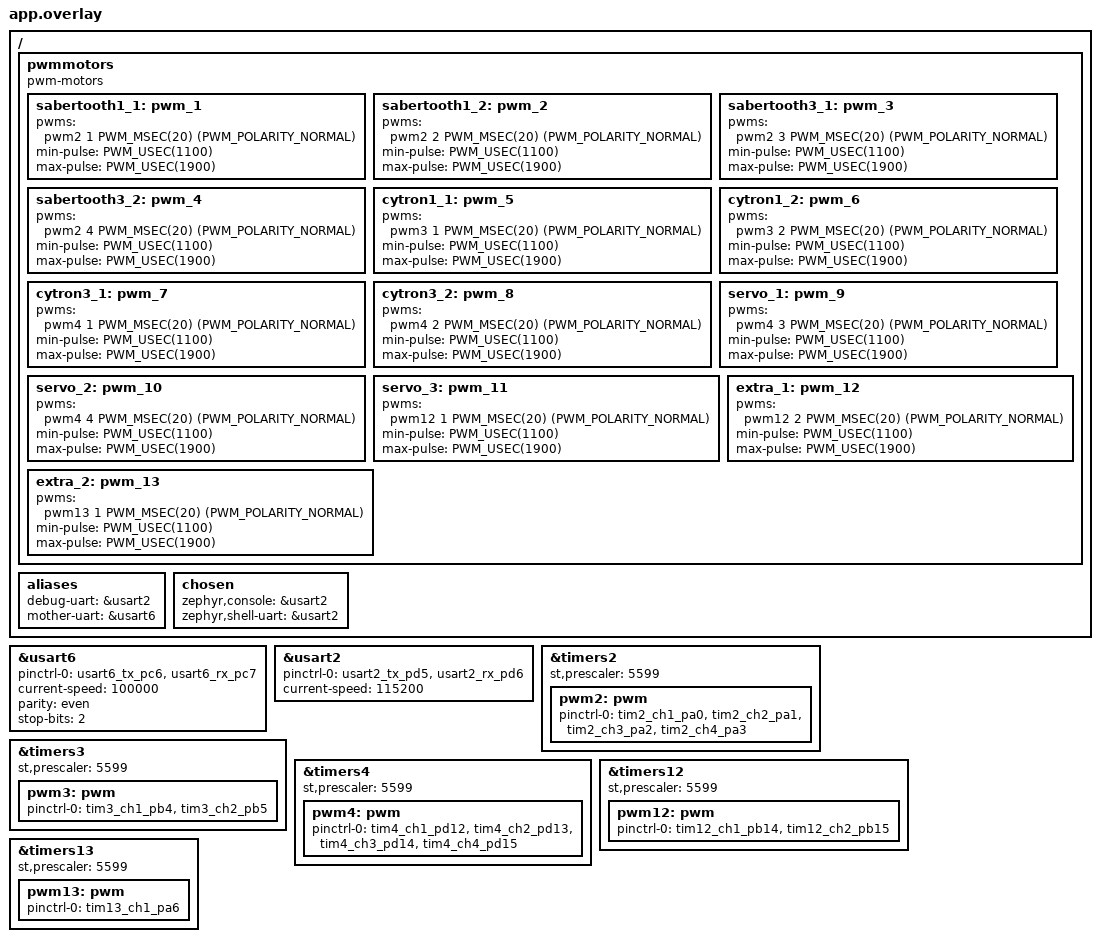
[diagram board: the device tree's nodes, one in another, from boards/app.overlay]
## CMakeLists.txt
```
cmake_minimum_required(VERSION 3.13.1)
set(DTC_OVERLAY_FILE "boards/app.overlay")
find_package(Zephyr REQUIRED HINTS $ENV{ZEPHYR_BASE})
project(R2-D2 LANGUAGES C)

target_sources(app PRIVATE src/UART_RAW_DATA_TEST.c)
```

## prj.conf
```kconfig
CONFIG_PRINTK=y
CONFIG_SERIAL=y
CONFIG_UART_INTERRUPT_DRIVEN=y

CONFIG_KYVERNITIS=y
CONFIG_CANSCRIBE=y
CONFIG_CANARD=y

CONFIG_CBPRINTF_FP_SUPPORT=y
CONFIG_REBOOT=y
```

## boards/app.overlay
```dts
#include <zephyr/dt-bindings/sensor/qdec_stm32.h>
/{
	pwmmotors {
		compatible = "pwm-motors";
		sabertooth1_1: pwm_1 {
			pwms  = <&pwm2 1 PWM_MSEC(20) (PWM_POLARITY_NORMAL)>;
			min-pulse = <PWM_USEC(1100)>;
			max-pulse = <PWM_USEC(1900)>;
		};
		sabertooth1_2: pwm_2 {
			pwms  = <&pwm2 2 PWM_MSEC(20) (PWM_POLARITY_NORMAL)>;
			min-pulse = <PWM_USEC(1100)>;
			max-pulse = <PWM_USEC(1900)>;
		};
		sabertooth3_1: pwm_3 {
			pwms  = <&pwm2 3 PWM_MSEC(20) (PWM_POLARITY_NORMAL)>;
			min-pulse = <PWM_USEC(1100)>;
			max-pulse = <PWM_USEC(1900)>;
		};
		sabertooth3_2: pwm_4 {
			pwms  = <&pwm2 4 PWM_MSEC(20) (PWM_POLARITY_NORMAL)>;
			min-pulse = <PWM_USEC(1100)>;
			max-pulse = <PWM_USEC(1900)>;
		};
		cytron1_1: pwm_5 {
			pwms  = <&pwm3 1 PWM_MSEC(20) (PWM_POLARITY_NORMAL)>;
			min-pulse = <PWM_USEC(1100)>;
			max-pulse = <PWM_USEC(1900)>;
		};
		cytron1_2: pwm_6 {
			pwms  = <&pwm3 2 PWM_MSEC(20) (PWM_POLARITY_NORMAL)>;
			min-pulse = <PWM_USEC(1100)>;
			max-pulse = <PWM_USEC(1900)>;
		};
		cytron3_1: pwm_7 {
			pwms  = <&pwm4 1 PWM_MSEC(20) (PWM_POLARITY_NORMAL)>;
			min-pulse = <PWM_USEC(1100)>;
			max-pulse = <PWM_USEC(1900)>;
		};
		cytron3_2: pwm_8 {
			pwms  = <&pwm4 2 PWM_MSEC(20) (PWM_POLARITY_NORMAL)>;
			min-pulse = <PWM_USEC(1100)>;
			max-pulse = <PWM_USEC(1900)>;
		};
		servo_1: pwm_9 {
			pwms  = <&pwm4 3 PWM_MSEC(20) (PWM_POLARITY_NORMAL)>;
			min-pulse = <PWM_USEC(1100)>;
			max-pulse = <PWM_USEC(1900)>;
		};
		servo_2: pwm_10 {
			pwms  = <&pwm4 4 PWM_MSEC(20) (PWM_POLARITY_NORMAL)>;
			min-pulse = <PWM_USEC(1100)>;
			max-pulse = <PWM_USEC(1900)>;
		};
		servo_3: pwm_11 {
			pwms  = <&pwm12 1 PWM_MSEC(20) (PWM_POLARITY_NORMAL)>;
			min-pulse = <PWM_USEC(1100)>;
			max-pulse = <PWM_USEC(1900)>;
		};

		extra_1: pwm_12 {
			pwms = <&pwm12 2 PWM_MSEC(20)  (PWM_POLARITY_NORMAL)>;
			min-pulse = <PWM_USEC(1100)>;
			max-pulse = <PWM_USEC(1900)>;
		};

		extra_2: pwm_13 {
			pwms = <&pwm13 1 PWM_MSEC(20)  (PWM_POLARITY_NORMAL)>;
			min-pulse = <PWM_USEC(1100)>;
			max-pulse = <PWM_USEC(1900)>;
		};
	};
	aliases {
			debug-uart = &usart2;
			mother-uart = &usart6;
	};
    chosen {
            zephyr,console = &usart2;
            zephyr,shell-uart = &usart2;
	};
};

&usart6 {
	pinctrl-0 = <&usart6_tx_pc6 &usart6_rx_pc7>;
	pinctrl-names= "default";
	status = "okay";
	current-speed = <100000>;
	parity = "even";
	stop-bits = "2";
};

&usart2 {
        pinctrl-0 = <&usart2_tx_pd5 &usart2_rx_pd6>;
        pinctrl-names= "default";
        status = "okay";
        current-speed = <115200>;
};

&timers2 {
	status = "okay";
	st,prescaler = <5599>;

	pwm2: pwm {
		status = "okay";
		pinctrl-0 = <&tim2_ch1_pa0 &tim2_ch2_pa1 &tim2_ch3_pa2 &tim2_ch4_pa3>;
		pinctrl-names = "default";
	};
};

&timers3 {
	status = "okay";
	st,prescaler = <5599>;

	pwm3: pwm {
		status = "okay";
		pinctrl-0 = <&tim3_ch1_pb4 &tim3_ch2_pb5>;
		pinctrl-names = "default";
	};
};

&timers4 {
	status = "okay";
	st,prescaler = <5599>;

	pwm4: pwm {
		status = "okay";
		pinctrl-0 = <&tim4_ch1_pd12 &tim4_ch2_pd13 &tim4_ch3_pd14 &tim4_ch4_pd15>;
		pinctrl-names = "default";
	};
};

&timers12 {
	status = "okay";
	st,prescaler = <5599>;

	pwm12: pwm {
		status = "okay";
		pinctrl-0 = <&tim12_ch1_pb14 &tim12_ch2_pb15>;
		pinctrl-names = "default";
	};
};

&timers13 {
	status = "okay";
	st,prescaler = <5599>;

	pwm13: pwm {
		status = "okay";
		pinctrl-0 = <&tim13_ch1_pa6>;
		pinctrl-names = "default";
	};
};
```

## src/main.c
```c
#include <zephyr/kernel.h>
#include <zephyr/device.h>
#include <kyvernitis/lib/kyvernitis.h>
#include <stdio.h>
#include <string.h>
#include "sbus_parse.c"
#include <zephyr/devicetree.h>
#include <zephyr/drivers/gpio.h>
#include <zephyr/drivers/sensor.h>
#include <zephyr/drivers/uart.h>

static const struct device *const uart_dev = DEVICE_DT_GET(DT_ALIAS(mother_uart)); // data from SBUS
static const struct device *const uart_debug = DEVICE_DT_GET(DT_ALIAS(debug_uart)); //debugger

/* DT spec for encoders */
// const struct device *const encoder_fr = DEVICE_DT_GET(DT_ALIAS(en_fr));
// const struct device *const encoder_fl = DEVICE_DT_GET(DT_ALIAS(en_fl));

/* DT spec for pwm motors */
#define PWM_MOTOR_SETUP(pwm_dev_id)                                                                \
	{.dev_spec = PWM_DT_SPEC_GET(pwm_dev_id),                                                  \
	 .min_pulse = DT_PROP(pwm_dev_id, min_pulse),                                              \
	 .max_pulse = DT_PROP(pwm_dev_id, max_pulse)},

struct pwm_motor motor[13] = {DT_FOREACH_CHILD(DT_PATH(pwmmotors), PWM_MOTOR_SETUP)};

K_MSGQ_DEFINE(uart_msgq, sizeof(uint8_t), 250, 1);

//struct mother_msg msg;
uint8_t message;
float linear_velocity_range[] = {-1.5, 1.5};
float angular_velocity_range[]= {-5.5,5.5};
float wheel_velocity_range[] = {-10.0, 10.0};
uint32_t pwm_range[] = {1120000, 1880000};
float la_speed_range[] = {-127.0, 127.0};
float angle_range[] = {-270, 270};
uint16_t channel_range[]={0,2047};
uint16_t* ch;

/* Global ticks for encoders */
//int64_t ticks_fr, ticks_fl;

struct DiffDriveTwist TIMEOUT_CMD = {
	.angular_z = 0,
	.linear_x = 0,
};


int sbus_parsing() {
	uint8_t packet[25],packet_pos=0,start = 0x0F, end = 0x00;

	k_msgq_get(&uart_msgq, &message,K_MSEC(4));

	if(message == start) 
	{
		for(packet_pos = 0; packet_pos < 25; packet_pos++) 
		{
			packet[packet_pos] = message;
			k_msgq_get(&uart_msgq, &message,K_MSEC(4));
		}
		// check if the last byte was 0x00
		ch = parse_buffer(packet);
		return 1;
	} 
	else 
	{
		return 0;
	}
}

void serial_cb(const struct device *dev, void *user_data)
{
	uint8_t c;
	
	if (!uart_irq_update(uart_dev)) 
	{
		return;
	}

	if (!uart_irq_rx_ready(uart_dev)) 
	{
		return;
	}

	while (uart_fifo_read(uart_dev, &c, 1) == 1) 
	{
        	k_msgq_put(&uart_msgq, &c, K_NO_WAIT);
	}
}

float sbus_velocity_interpolation(uint16_t channel_input,float *velocity_range)
{

	if (channel_input > channel_range[1])
	{
		return velocity_range[1];
	}

	if (channel_input < channel_range[0])
	{
		return velocity_range[0];
	}

	if (channel_input < 1005 && channel_input > 995) 
	{
		return (velocity_range[0] + velocity_range[1]) / 2;
	}
	float dchannel = channel_range[1] - channel_range[0];
	float dvel = velocity_range[1] - velocity_range[0];

	float  vel_interp = velocity_range[0] + (dvel / dchannel) * (channel_input - channel_range[0]);
	return vel_interp;
}

int feedback_callback(float *feedback_buffer, int buffer_len, int wheels_per_side)
{
	return 0;
}

int velocity_callback(const float *velocity_buffer, int buffer_len, int wheels_per_side)
{
	if (buffer_len < wheels_per_side * 2) 
	{
		return 1;
	}

	const int i = 0;
	if (pwm_motor_write(&(motor[i]), velocity_pwm_interpolation(*(velocity_buffer + i), wheel_velocity_range, pwm_range))) 
	{
		printk("Drive: Unable to write pwm pulse to Left : %d", i);
		return 1;
	}
	if (pwm_motor_write(&(motor[i + 1]), velocity_pwm_interpolation(*(velocity_buffer + wheels_per_side + i), wheel_velocity_range, pwm_range))) 
	{
		printk("Drive: Unable to write pwm pulse to Right : %d", i);
		return 1;
	}
	return 0;
}
int main(){
	int err,i,flag=0;
	uint64_t drive_timestamp = 0;
	uint64_t time_last_drive_update = 0;

	struct DiffDriveConfig drive_config = {
		.wheel_separation = 0.77f,
		.wheel_separation_multiplier = 1,
		.wheel_radius = 0.15f,
		.wheels_per_side = 2,
		.command_timeout_seconds = 2,
		.left_wheel_radius_multiplier = 1,
		.right_wheel_radius_multiplier = 1,
		.update_type = POSITION_FEEDBACK,
	};

	struct DiffDriveTwist cmd = {
            .angular_z = 0,
            .linear_x = 0,
	};

	if (!device_is_ready(uart_dev)) 
	{
		printk( "UART device not ready");
	}

	for (size_t i = 0U; i < ARRAY_SIZE(motor); i++) 
	{
		if (!pwm_is_ready_dt(&(motor[i].dev_spec))) 
		{
			printk( "PWM: Motor %s is not ready", motor[i].dev_spec.dev->name);
		}
	}

	err = uart_irq_callback_user_data_set(uart_dev, serial_cb, NULL);
	
	if(err<0)
	{
		if (err == -ENOTSUP) 
		{
			printk("Interrupt-driven UART API support not enabled");
		} 
		else if (err == -ENOSYS) 
		{
			printk("UART device does not support interrupt-driven API");
		}
		else 
		{
			printk("Error setting UART callback: %d", err);
		}
	}


	uart_irq_rx_enable(uart_dev);
	
	struct DiffDrive *drive = diffdrive_init(&drive_config, feedback_callback, velocity_callback);	

	for (size_t i = 0U; i < ARRAY_SIZE(motor); i++) 
	{
		if (pwm_motor_write(&(motor[i]), 1500000)) 
		{
			printk("Unable to write pwm pulse to PWM Motor : %d", i);
		}
	}

	printk("Initialization completed successfully!");
	
	while(true)
	{
		flag=sbus_parsing();
		if(flag == 0)
		{
			printk("\nError:Could not find start bit"); 
			continue;
		}
		 else 
		 {
			 for(i = 0 ; i < 16 ; i++)
			 {
				 if(i == 2)
				 {
					cmd.linear_x = sbus_velocity_interpolation(ch[i],linear_velocity_range);
					printk("%d: %d    %0.2f   ",i,ch[i],cmd.linear_x);
				 }
				if(i == 0)
				{
					cmd.angular_z = sbus_velocity_interpolation(ch[i],angular_velocity_range);
					printk("%d: %d    %0.2f   ",i,ch[i], cmd.angular_z);
				}
		 	}
			printk("\n");
		 }

		drive_timestamp = k_uptime_get();
		err = diffdrive_update(drive, cmd, time_last_drive_update);
		time_last_drive_update = k_uptime_get() - drive_timestamp;
	}
}
```

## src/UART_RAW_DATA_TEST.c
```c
#include <zephyr/kernel.h>
#include <zephyr/device.h>
#include <zephyr/drivers/uart.h>
#include <kyvernitis/lib/kyvernitis.h>
#include <stdio.h>
#include <string.h>

static const struct device *const uart_dev = DEVICE_DT_GET(DT_ALIAS(mother_uart));
static const struct device *const uart_debug = DEVICE_DT_GET(DT_ALIAS(debug_uart));
//#define UART_MSG_SIZE (sizeof(uint8_t)*25)
K_MSGQ_DEFINE(uart_msgq, sizeof(uint8_t), 100, 1);
//struct mother_msg msg;
uint8_t message;
	//void recv_str(const struct device *uart, char *str)
	//{
	//        char *head = str;
	//        char c;
	//
	//        while (!uart_poll_in(uart, &c)) {
	//                *head++ = c;
	//        }
	//        *head = '\0';
	//
	//        printk("Device %s received: \"%s\"\n", uart->name, str);
	//}
	//
	//
void serial_cb(const struct device *dev, void *user_data){
	uint8_t c;
	int buf_pos=0;
	if (!uart_irq_update(uart_dev)) {
		return;
	}

	if (!uart_irq_rx_ready(uart_dev)) {
		return;
	}
	while (uart_fifo_read(uart_dev, &c, 1) == 1) {
        	k_msgq_put(&uart_msgq, &c, K_MSEC(4));
	//	printk("print c:%hhx\n",c);
	}
}
int main(){
	int err;
	printk("I am alive");
	if (!device_is_ready(uart_dev)) 
	{
		printk( "UART device not ready");
	}
	err = uart_irq_callback_user_data_set(uart_dev, serial_cb, NULL);
	if(err<0)
	{
		printk("Error setting irq on uart_dev\n");
	}
	uart_irq_rx_enable(uart_dev);
	
	while(true){
		k_msgq_get(&uart_msgq, &message,K_MSEC(4));
//		if(message==0x0f){
			for(int i=0;i<25;i++)
			{	
				printk("%02x ", message);
				k_msgq_get(&uart_msgq, &message,K_MSEC(4));
			}
			printk("\n");
//		}
	}
}
```

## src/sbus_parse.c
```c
#include <stdio.h>
#include <stdint.h>

// variable to store channel 
uint16_t channel[16];

// creating 11 bit channel
uint16_t *parse_buffer(uint8_t buff[]) { 
		
	// masking byte shiftings bits (value in hexa '0x07FF')
	uint16_t mask = 0x7ff;

	// creating channels 
        channel[0]  = ((buff[1] | buff[2]<<8)                 & mask);
        channel[1]  = ((buff[2]>>3 | buff[3]<<5)              & mask);
        channel[2]  = ((buff[3]>>6 | buff[4]<<2 | buff[5]<<10) & mask);
        channel[3]  = ((buff[5]>>1 | buff[6]<<7)              & mask);
        channel[4]  = ((buff[6]>>4 | buff[7]<<4)              & mask);
        channel[5]  = ((buff[7]>>7 | buff[8]<<1 | buff[9]<<9)  & mask);
        channel[6]  = ((buff[9]>>2 | buff[10]<<6)             & mask);
        channel[7]  = ((buff[10]>>5| buff[11]<<3)             & mask);
        channel[8]  = ((buff[12]   | buff[13]<<8)             & mask);
        channel[9]  = ((buff[13]>>3| buff[14]<<5)             & mask);
        channel[10] = ((buff[14]>>6| buff[15]<<2| buff[16]<<10)& mask);
        channel[11] = ((buff[16]>>1| buff[17]<<7)             & mask);
        channel[12] = ((buff[17]>>4| buff[18]<<4)             & mask);
        channel[13] = ((buff[18]>>7| buff[19]<<1| buff[20]<<9) & mask);
        channel[14] = ((buff[20]>>2| buff[21]<<6)             & mask);
        channel[15] = ((buff[21]>>5| buff[22]<<3)             & mask);

	return channel;
}

// to check parity byte
int parity_checker(int parity)
{
	uint8_t failsafe, frame_lost, bit0, bit1, ct;

	// extracting first two bit of parity byte
	bit0 = parity>>7;
	bit1 = (parity>>6)<<1;

	if (bit0 == 0 && bit1 == 0)
		return 0;

	else
		return 1;
}
```

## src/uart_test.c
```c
#include <zephyr/kernel.h>
#include <zephyr/device.h>
#include <kyvernitis/lib/kyvernitis.h>
#include <stdio.h>
#include <string.h>
#include "sbus_parse.c"
#include <zephyr/devicetree.h>
#include <zephyr/drivers/gpio.h>
#include <zephyr/drivers/sensor.h>
#include <zephyr/drivers/uart.h>

static const struct device *const uart_dev = DEVICE_DT_GET(DT_ALIAS(mother_uart));
static const struct device *const uart_debug = DEVICE_DT_GET(DT_ALIAS(debug_uart));

/* DT spec for encoders */
// const struct device *const encoder_fr = DEVICE_DT_GET(DT_ALIAS(en_fr));
// const struct device *const encoder_fl = DEVICE_DT_GET(DT_ALIAS(en_fl));

/* DT spec for pwm motors */
#define PWM_MOTOR_SETUP(pwm_dev_id)                                                                \
	{.dev_spec = PWM_DT_SPEC_GET(pwm_dev_id),                                                  \
	 .min_pulse = DT_PROP(pwm_dev_id, min_pulse),                                              \
	 .max_pulse = DT_PROP(pwm_dev_id, max_pulse)},

struct pwm_motor motor[13] = {DT_FOREACH_CHILD(DT_PATH(pwmmotors), PWM_MOTOR_SETUP)};
//#define UART_MSG_SIZE (sizeof(uint8_t)*25)

K_MSGQ_DEFINE(uart_msgq, sizeof(uint8_t), 250, 1);

//struct mother_msg msg;
uint8_t message;
float linear_velocity_range[] = {-1.5, 1.5};
float angular_velocity_range[]= {-5.5,5.5};
float wheel_velocity_range[] = {-10.0, 10.0};
uint32_t pwm_range[] = {1120000, 1880000};
float la_speed_range[] = {-127.0, 127.0};
float angle_range[] = {-270, 270};
uint16_t channel_range[]={0,2047};
uint16_t* ch;

/* Global ticks for encoders */
int64_t ticks_fr, ticks_fl;

struct DiffDriveTwist TIMEOUT_CMD = {
	.angular_z = 0,
	.linear_x = 0,
};


int sbus_parsing() {
	uint8_t packet[25],packet_pos=0,start = 0x0F, end = 0x00;

	k_msgq_get(&uart_msgq, &message,K_MSEC(4));

	if(message == start) 
	{
		for(packet_pos = 0; packet_pos < 25; packet_pos++) 
		{
			packet[packet_pos] = message;
			k_msgq_get(&uart_msgq, &message,K_MSEC(4));
		}
		// check if the last byte was 0x00
		ch = parse_buffer(packet);
		return 1;
	} 
	else 
	{
		return 0;
	}
}

void serial_cb(const struct device *dev, void *user_data)
{
	uint8_t c;
	uint8_t data[25];
	int buf_pos=0;
	
	if (!uart_irq_update(uart_dev)) 
	{
		return;
	}

	if (!uart_irq_rx_ready(uart_dev)) {
		return;
	}

	while (uart_fifo_read(uart_dev, &c, 1) == 1) 
	{
        	k_msgq_put(&uart_msgq, &c, K_NO_WAIT);
	}
}

float sbus_velocity_interpolation(uint16_t channel_input,float *velocity_range)
{

	if (channel_input > channel_range[1])
	{
		return velocity_range[1];
	}

	if (channel_input < channel_range[0])
	{
		return velocity_range[0];
	}

	if (channel_input < 1005 && channel_input > 995) 
	{
		return (velocity_range[0] + velocity_range[1]) / 2;
	}
	float dchannel = channel_range[1] - channel_range[0];
	float dvel = velocity_range[1] - velocity_range[0];

	float  vel_interp = velocity_range[0] + (dvel / dchannel) * (channel_input - channel_range[0]);
	return vel_interp;
}

int feedback_callback(float *feedback_buffer, int buffer_len, int wheels_per_side)
{
	return 0;
}

int velocity_callback(const float *velocity_buffer, int buffer_len, int wheels_per_side)
{
	if (buffer_len < wheels_per_side * 2) 
	{
		return 1;
	}

	const int i = 0;
	if (pwm_motor_write(&(motor[i]), velocity_pwm_interpolation(*(velocity_buffer + i), wheel_velocity_range, pwm_range))) 
	{
		//log_uart(T_MOTHER_ERROR, "Drive: Unable to write pwm pulse to Left : %d", i);
		return 1;
	}
	if (pwm_motor_write(&(motor[i + 1]), velocity_pwm_interpolation(*(velocity_buffer + wheels_per_side + i), wheel_velocity_range, pwm_range))) 
	{
		//log_uart(T_MOTHER_ERROR, "Drive: Unable to write pwm pulse to Right : %d", i);
		return 1;
	}
	return 0;
}
int main(){
	int err,i,flag=0;
	uint64_t drive_timestamp = 0;
	uint64_t time_last_drive_update = 0;

	struct DiffDriveConfig drive_config = {
		.wheel_separation = 0.77f,
		.wheel_separation_multiplier = 1,
		.wheel_radius = 0.15f,
		.wheels_per_side = 2,
		.command_timeout_seconds = 2,
		.left_wheel_radius_multiplier = 1,
		.right_wheel_radius_multiplier = 1,
		.update_type = POSITION_FEEDBACK,
	};

	struct DiffDriveTwist cmd = {
            .angular_z = 0,
            .linear_x = 0,
	};

	if (!device_is_ready(uart_dev)) 
	{
		printk( "UART device not ready");
	}

	for (size_t i = 0U; i < ARRAY_SIZE(motor); i++) 
	{
		if (!pwm_is_ready_dt(&(motor[i].dev_spec))) 
		{
			printk( "PWM: Motor %s is not ready", motor[i].dev_spec.dev->name);
		}
	}

	err = uart_irq_callback_user_data_set(uart_dev, serial_cb, NULL);
	
	if(err<0)
	{
		printk("Error");
	}

	uart_irq_rx_enable(uart_dev);
	
	struct DiffDrive *drive = diffdrive_init(&drive_config, feedback_callback, velocity_callback);	

	for (size_t i = 0U; i < ARRAY_SIZE(motor); i++) 
	{
		if (pwm_motor_write(&(motor[i]), 1500000)) 
		{
			printk("Unable to write pwm pulse to PWM Motor : %d", i);
		}
	}

	while(true)
	{
		flag=sbus_parsing();
		if(flag == 0)
		{
			//printk("\nError:Could not find start bit"); 
			continue;
		}
		 else 
		 {
			 for(i = 0 ; i < 16 ; i++)
			 {
				 if(i == 2)
				 {
					cmd.linear_x = sbus_velocity_interpolation(ch[i],linear_velocity_range);
					printk("%d: %d    %0.2f   ",i,ch[i],cmd.linear_x);
				 }
				if(i == 0)
				{
					cmd.angular_z = sbus_velocity_interpolation(ch[i],angular_velocity_range);
					printk("%d: %d    %0.2f   ",i,ch[i], cmd.angular_z);
				}
		 	}
			printk("\n");
		 }

		drive_timestamp = k_uptime_get();
		err = diffdrive_update(drive, cmd, time_last_drive_update);
		time_last_drive_update = k_uptime_get() - drive_timestamp;
	}
}
```
